# STM32H733xx register map
File version: 1.0
Registers are 32-bit, access not given, reset 0x0 unless marked. A register's access mark holds for its fields unless they carry their own. Offsets are from the block's base; [hi:lo] are bit positions; {n}, {i} and the like mark numbered series.

## DMAMUX1
Base 0x40020800
Same registers: DMAMUX2 0x58025800
0x00 CCR0
0x04 CCR1
0x08 CCR2
0x0C CCR3
0x10 CCR4
0x14 CCR5
0x18 CCR6
0x1C CCR7
0x20 CCR8
0x24 CCR9
0x28 CCR0
0x2C CCR1
0x30 CCR2
0x34 CCR3
0x38 CCR4
0x3C CCR5
0x80 CCRs
0x100 CCR0
0x104 CCR1
0x108 CCR2
0x10C CCR3
0x110 CCR4
0x114 CCR5
0x118 CCR6
0x11C CCR7
0x140 CCRs
0x18005000 CCR0

## ADC1
Base 0x40022000
Same registers: ADC2 0x40022100, ADC3 0x58026000
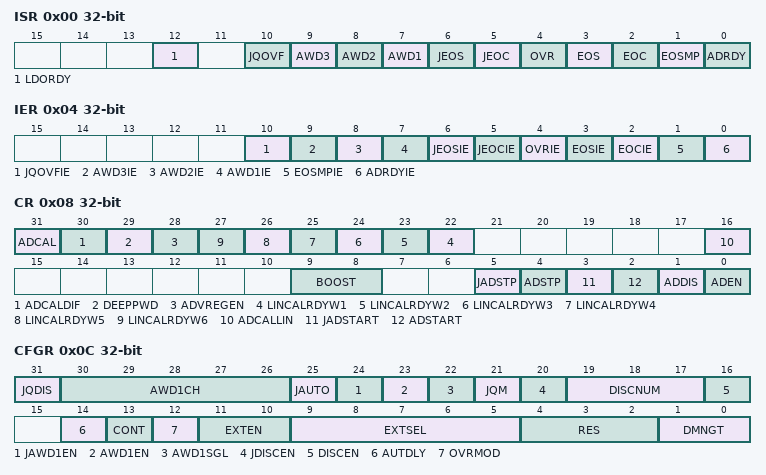
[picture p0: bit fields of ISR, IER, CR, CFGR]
0x00 ISR
  [12] LDORDY, [10] JQOVF, [9] AWD3, [8] AWD2, [7] AWD1, [6] JEOS, [5] JEOC, [4] OVR, [3] EOS, [2] EOC, [1] EOSMP, [0] ADRDY
0x04 IER
  [10] JQOVFIE, [9] AWD3IE, [8] AWD2IE, [7] AWD1IE, [6] JEOSIE, [5] JEOCIE, [4] OVRIE, [3] EOSIE, [2] EOCIE, [1] EOSMPIE, [0] ADRDYIE
0x08 CR
  [31] ADCAL, [30] ADCALDIF, [29] DEEPPWD, [28] ADVREGEN, [n+21] LINCALRDYW{n} (n=1..6), [16] ADCALLIN, [9:8] BOOST, [5] JADSTP, [4] ADSTP, [3] JADSTART, [2] ADSTART, [1] ADDIS, [0] ADEN
0x0C CFGR
  [31] JQDIS, [30:26] AWD1CH, [25] JAUTO, [24] JAWD1EN, [23] AWD1EN, [22] AWD1SGL, [21] JQM, [20] JDISCEN, [19:17] DISCNUM, [16] DISCEN, [14] AUTDLY, [13] CONT, [12] OVRMOD, [11:10] EXTEN, [9:5] EXTSEL, [4:2] RES, [1:0] DMNGT
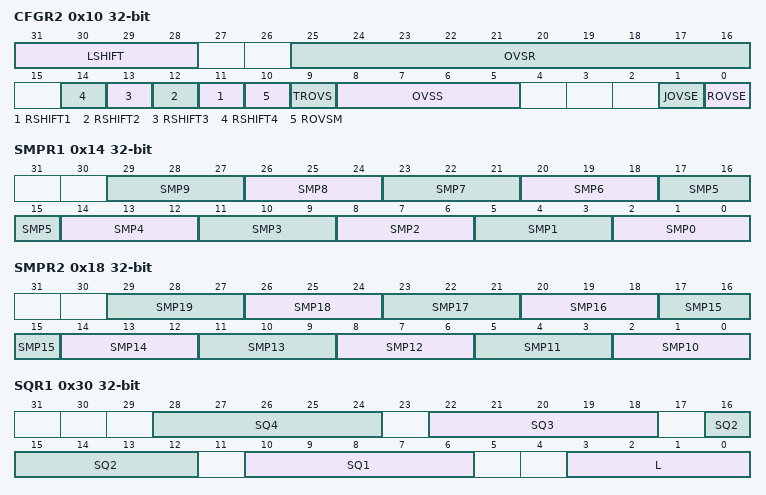
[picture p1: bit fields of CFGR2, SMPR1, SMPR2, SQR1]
0x10 CFGR2
  [31:28] LSHIFT, [25:16] OVSR, [n+10] RSHIFT{n} (n=1..4), [10] ROVSM, [9] TROVS, [8:5] OVSS, [1] JOVSE, [0] ROVSE
0x14 SMPR1
  [3n+2:3n] SMP{n} (n=0..9)
0x18 SMPR2
  [3n-28:3n-30] SMP{n} (n=10..19)
0x1C PCSEL_RES0
0x20 LTR1_TR1
0x24 HTR1_TR2
0x28 RES1_TR3
0x30 SQR1
  [6n+4:6n] SQ{n} (n=1..4), [3:0] L
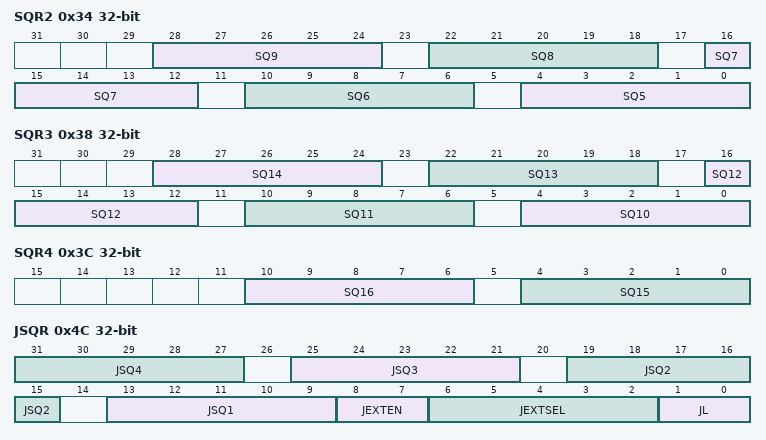
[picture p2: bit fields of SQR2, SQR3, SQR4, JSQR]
0x34 SQR2
  [6n-26:6n-30] SQ{n} (n=5..9)
0x38 SQR3
  [6n-56:6n-60] SQ{n} (n=10..14)
0x3C SQR4
  [10:6] SQ16, [4:0] SQ15
0x40 DR
  [31:0] RDATA
0x4C JSQR
  [6n+7:6n+3] JSQ{n} (n=1..4), [8:7] JEXTEN, [6:2] JEXTSEL, [1:0] JL
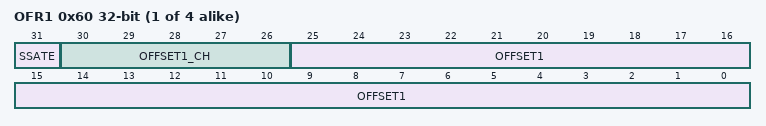
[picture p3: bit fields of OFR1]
{0x5C+4i} OFR{i} (i=1..4)
  [31] SSATE, [30:26] OFFSET{i}_CH, [25:0] OFFSET{i}
{0x7C+4i} JDR{i} (i=1..4)
  [31:0] JDATA
0xA0 AWD2CR
  [19:0] AWD2CH
0xA4 AWD3CR
  [19:0] AWD3CH
0xB0 LTR2_DIFSEL
0xB4 HTR2_CALFACT
0xB8 LTR3_RES10
0xBC HTR3_RES11
0xC0 DIFSEL_RES12
0xC4 CALFACT_RES13
0xC8 CALFACT2_RES14

## ADC12_COMMON
Base 0x40022300
Same registers: ADC3_COMMON 0x58026300
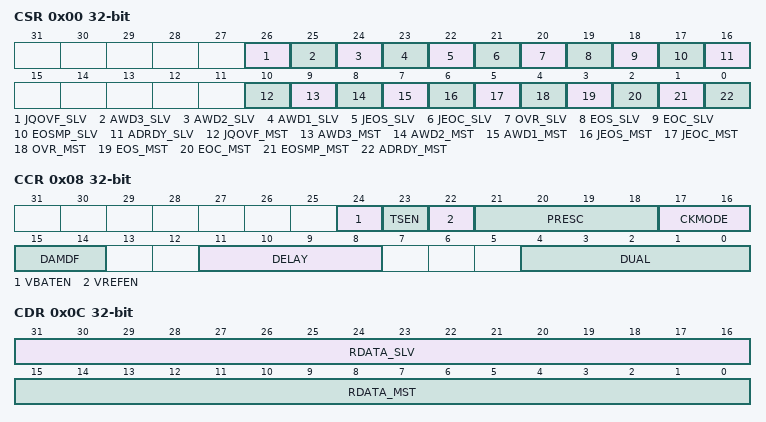
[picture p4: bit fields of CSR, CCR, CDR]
0x00 CSR
  [26] JQOVF_SLV, [25] AWD3_SLV, [24] AWD2_SLV, [23] AWD1_SLV, [22] JEOS_SLV, [21] JEOC_SLV, [20] OVR_SLV, [19] EOS_SLV, [18] EOC_SLV, [17] EOSMP_SLV, [16] ADRDY_SLV, [10] JQOVF_MST, [9] AWD3_MST, [8] AWD2_MST, [7] AWD1_MST, [6] JEOS_MST, [5] JEOC_MST, [4] OVR_MST, [3] EOS_MST, [2] EOC_MST, [1] EOSMP_MST, [0] ADRDY_MST
0x08 CCR
  [24] VBATEN, [23] TSEN, [22] VREFEN, [21:18] PRESC, [17:16] CKMODE, [15:14] DAMDF, [11:8] DELAY, [4:0] DUAL
0x0C CDR
  [31:16] RDATA_SLV, [15:0] RDATA_MST
0x10 CDR2
  [31:0] RDATA_ALT

## USB1_OTG_HS
Base 0x40040000
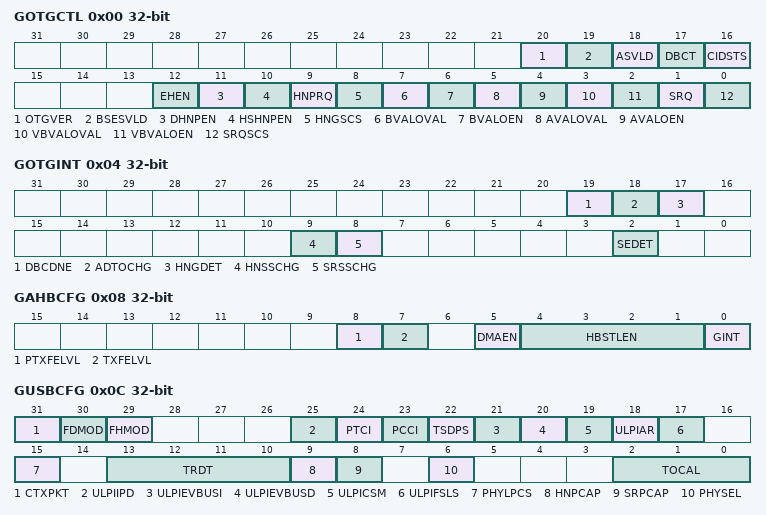
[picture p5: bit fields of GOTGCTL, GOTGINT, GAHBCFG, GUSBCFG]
0x00 GOTGCTL
  [20] OTGVER, [19] BSESVLD, [18] ASVLD, [17] DBCT, [16] CIDSTS, [12] EHEN, [11] DHNPEN, [10] HSHNPEN, [9] HNPRQ, [8] HNGSCS, [7] BVALOVAL, [6] BVALOEN, [5] AVALOVAL, [4] AVALOEN, [3] VBVALOVAL, [2] VBVALOEN, [1] SRQ, [0] SRQSCS
0x04 GOTGINT
  [19] DBCDNE, [18] ADTOCHG, [17] HNGDET, [9] HNSSCHG, [8] SRSSCHG, [2] SEDET
0x08 GAHBCFG
  [8] PTXFELVL, [7] TXFELVL, [5] DMAEN, [4:1] HBSTLEN, [0] GINT
0x0C GUSBCFG
  [31] CTXPKT, [30] FDMOD, [29] FHMOD, [25] ULPIIPD, [24] PTCI, [23] PCCI, [22] TSDPS, [21] ULPIEVBUSI, [20] ULPIEVBUSD, [19] ULPICSM, [18] ULPIAR, [17] ULPIFSLS, [15] PHYLPCS, [13:10] TRDT, [9] HNPCAP, [8] SRPCAP, [6] PHYSEL, [2:0] TOCAL
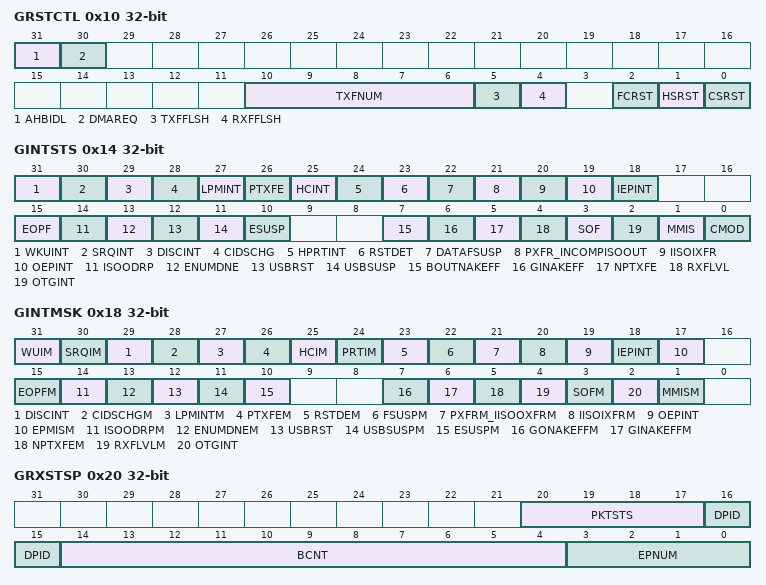
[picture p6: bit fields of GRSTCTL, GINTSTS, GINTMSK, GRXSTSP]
0x10 GRSTCTL
  [31] AHBIDL, [30] DMAREQ, [10:6] TXFNUM, [5] TXFFLSH, [4] RXFFLSH, [2] FCRST, [1] HSRST, [0] CSRST
0x14 GINTSTS
  [31] WKUINT, [30] SRQINT, [29] DISCINT, [28] CIDSCHG, [27] LPMINT, [26] PTXFE, [25] HCINT, [24] HPRTINT, [23] RSTDET, [22] DATAFSUSP, [21] PXFR_INCOMPISOOUT, [20] IISOIXFR, [19] OEPINT, [18] IEPINT, [15] EOPF, [14] ISOODRP, [13] ENUMDNE, [12] USBRST, [11] USBSUSP, [10] ESUSP, [7] BOUTNAKEFF, [6] GINAKEFF, [5] NPTXFE, [4] RXFLVL, [3] SOF, [2] OTGINT, [1] MMIS, [0] CMOD
0x18 GINTMSK
  [31] WUIM, [30] SRQIM, [29] DISCINT, [28] CIDSCHGM, [27] LPMINTM, [26] PTXFEM, [25] HCIM, [24] PRTIM, [23] RSTDEM, [22] FSUSPM, [21] PXFRM_IISOOXFRM, [20] IISOIXFRM, [19] OEPINT, [18] IEPINT, [17] EPMISM, [15] EOPFM, [14] ISOODRPM, [13] ENUMDNEM, [12] USBRST, [11] USBSUSPM, [10] ESUSPM, [7] GONAKEFFM, [6] GINAKEFFM, [5] NPTXFEM, [4] RXFLVLM, [3] SOFM, [2] OTGINT, [1] MMISM
0x1C GRXSTSR
0x20 GRXSTSP
  [20:17] PKTSTS, [16:15] DPID, [14:4] BCNT, [3:0] EPNUM
0x24 GRXFSIZ
  [15:0] RXFD
0x28 DIEPTXF0_HNPTXFSIZ
0x2C HNPTXSTS
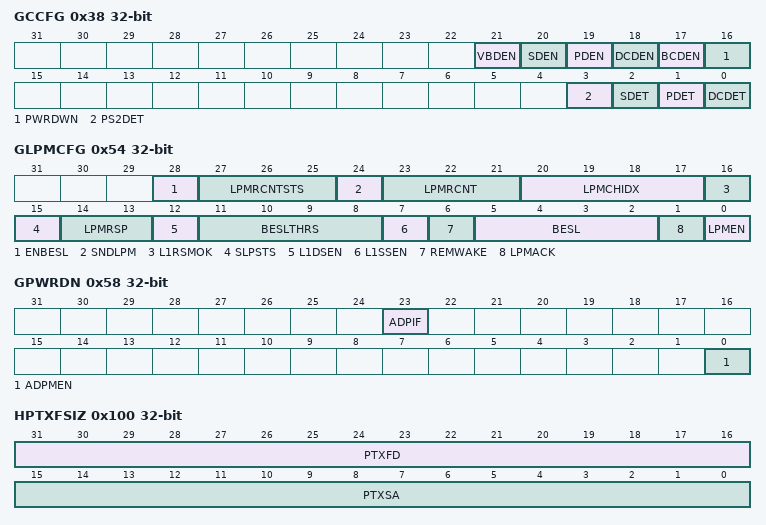
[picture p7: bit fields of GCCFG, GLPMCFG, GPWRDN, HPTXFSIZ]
0x38 GCCFG
  [21] VBDEN, [20] SDEN, [19] PDEN, [18] DCDEN, [17] BCDEN, [16] PWRDWN, [3] PS2DET, [2] SDET, [1] PDET, [0] DCDET
0x3C CID
  [31:0] PRODUCT_ID
0x40 GSNPSID
{0x40+4i} GHWCFG{i} (i=1..3)
0x54 GLPMCFG
  [28] ENBESL, [27:25] LPMRCNTSTS, [24] SNDLPM, [23:21] LPMRCNT, [20:17] LPMCHIDX, [16] L1RSMOK, [15] SLPSTS, [14:13] LPMRSP, [12] L1DSEN, [11:8] BESLTHRS, [7] L1SSEN, [6] REMWAKE, [5:2] BESL, [1] LPMACK, [0] LPMEN
0x58 GPWRDN
  [23] ADPIF, [0] ADPMEN
0x5C GDFIFOCFG
0x60 GADPCTL
0x100 HPTXFSIZ
  [31:16] PTXFD, [15:0] PTXSA
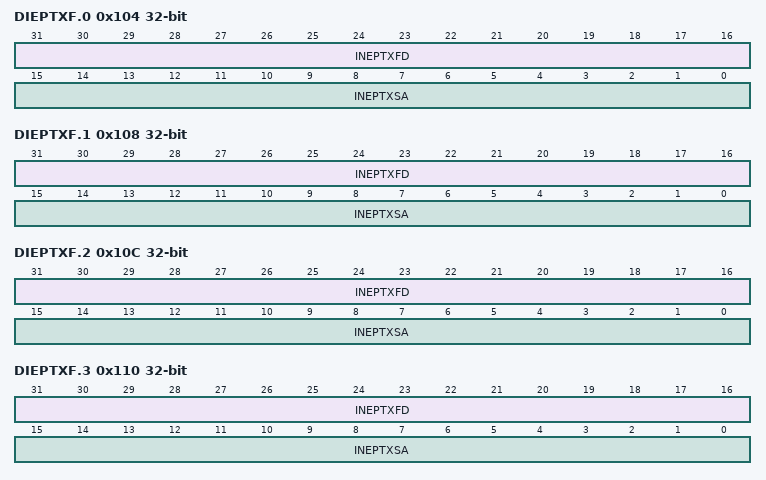
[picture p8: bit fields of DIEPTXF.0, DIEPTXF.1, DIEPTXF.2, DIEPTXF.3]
0x104 DIEPTXF.0
  [31:16] INEPTXFD, [15:0] INEPTXSA
0x108 DIEPTXF.1
  [31:16] INEPTXFD, [15:0] INEPTXSA
0x10C DIEPTXF.2
  [31:16] INEPTXFD, [15:0] INEPTXSA
0x110 DIEPTXF.3
  [31:16] INEPTXFD, [15:0] INEPTXSA
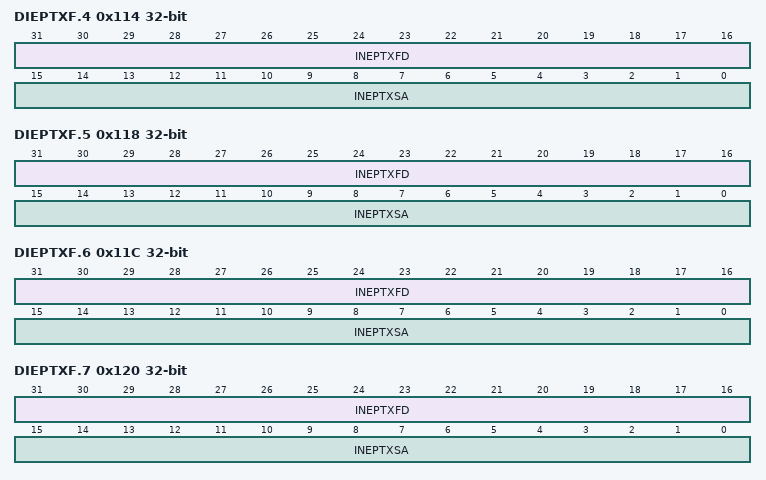
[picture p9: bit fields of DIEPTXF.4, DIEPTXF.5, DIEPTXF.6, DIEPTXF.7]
0x114 DIEPTXF.4
  [31:16] INEPTXFD, [15:0] INEPTXSA
0x118 DIEPTXF.5
  [31:16] INEPTXFD, [15:0] INEPTXSA
0x11C DIEPTXF.6
  [31:16] INEPTXFD, [15:0] INEPTXSA
0x120 DIEPTXF.7
  [31:16] INEPTXFD, [15:0] INEPTXSA
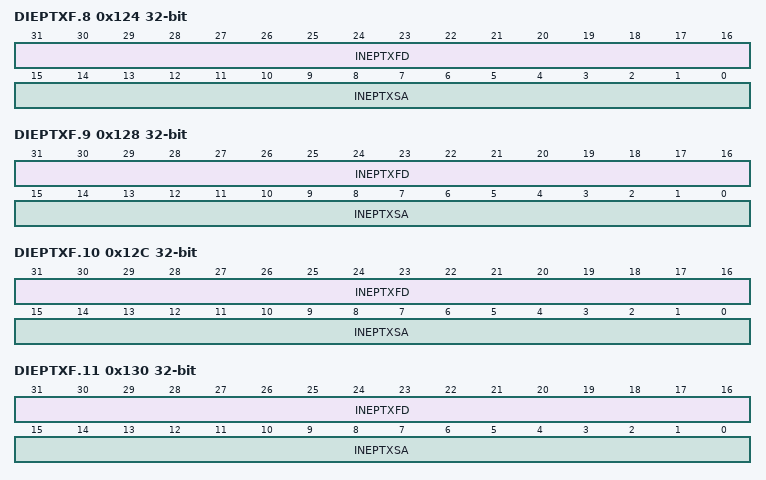
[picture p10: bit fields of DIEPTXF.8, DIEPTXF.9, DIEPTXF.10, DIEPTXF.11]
0x124 DIEPTXF.8
  [31:16] INEPTXFD, [15:0] INEPTXSA
0x128 DIEPTXF.9
  [31:16] INEPTXFD, [15:0] INEPTXSA
0x12C DIEPTXF.10
  [31:16] INEPTXFD, [15:0] INEPTXSA
0x130 DIEPTXF.11
  [31:16] INEPTXFD, [15:0] INEPTXSA
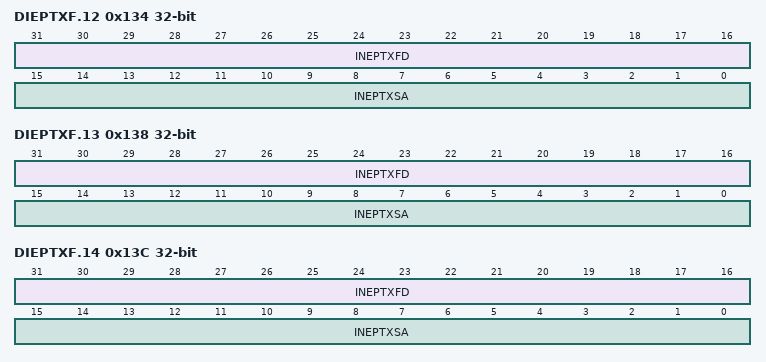
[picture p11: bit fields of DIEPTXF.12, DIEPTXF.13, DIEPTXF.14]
0x134 DIEPTXF.12
  [31:16] INEPTXFD, [15:0] INEPTXSA
0x138 DIEPTXF.13
  [31:16] INEPTXFD, [15:0] INEPTXSA
0x13C DIEPTXF.14
  [31:16] INEPTXFD, [15:0] INEPTXSA
